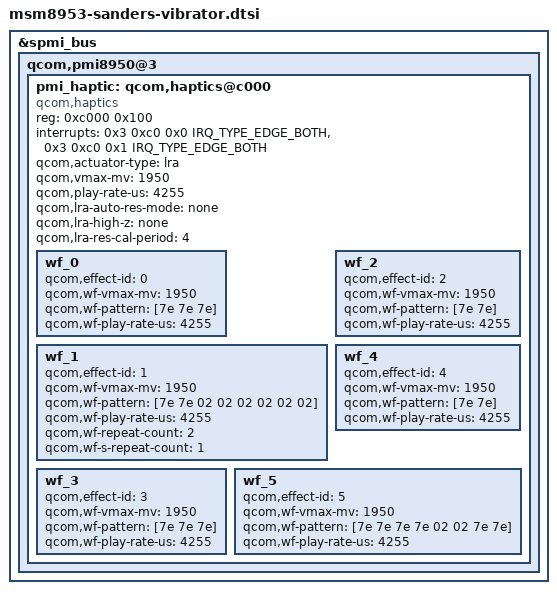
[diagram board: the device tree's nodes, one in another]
&spmi_bus {
	qcom,pmi8950@3 {
		/delete-node/ qcom,haptics@c000;

		pmi_haptic: qcom,haptics@c000 {
			compatible = "qcom,haptics";
			reg = <0xc000 0x100>;
			interrupts = <0x3 0xc0 0x0 IRQ_TYPE_EDGE_BOTH>,
				     <0x3 0xc0 0x1 IRQ_TYPE_EDGE_BOTH>;
			interrupt-names = "hap-sc-irq", "hap-play-irq";

			qcom,actuator-type = "lra";
			qcom,vmax-mv = <1950>;
			qcom,play-rate-us = <4255>;

			qcom,lra-auto-res-mode = "none";
			qcom,lra-high-z = "none";
			qcom,lra-res-cal-period = <4>;

			wf_0 {
				/* CLICK */
				qcom,effect-id = <0>;
				qcom,wf-vmax-mv = <1950>;
				qcom,wf-pattern = [7e 7e 7e];
				qcom,wf-play-rate-us = <4255>;
			};
			wf_1 {
				/* DOUBLE CLICK */
				qcom,effect-id = <1>;
				qcom,wf-vmax-mv = <1950>;
				qcom,wf-pattern = [7e 7e 02 02 02 02 02 02];
				qcom,wf-play-rate-us = <4255>;
				qcom,wf-repeat-count = <2>;
				qcom,wf-s-repeat-count = <1>;
			};
			wf_2 {
				/* TICK */
				qcom,effect-id = <2>;
				qcom,wf-vmax-mv = <1950>;
				qcom,wf-pattern = [7e 7e];
				qcom,wf-play-rate-us = <4255>;
			};
			wf_3 {
				/* THUD */
				qcom,effect-id = <3>;
				qcom,wf-vmax-mv = <1950>;
				qcom,wf-pattern = [7e 7e 7e];
				qcom,wf-play-rate-us = <4255>;
			};
			wf_4 {
				/* POP */
				qcom,effect-id = <4>;
				qcom,wf-vmax-mv = <1950>;
				qcom,wf-pattern = [7e 7e];
				qcom,wf-play-rate-us = <4255>;
			};
			wf_5 {
				/* HEAVY CLICK */
				qcom,effect-id = <5>;
				qcom,wf-vmax-mv = <1950>;
				qcom,wf-pattern = [7e 7e 7e 7e 02 02 7e 7e];
				qcom,wf-play-rate-us = <4255>;
			};
		};
	};
};
